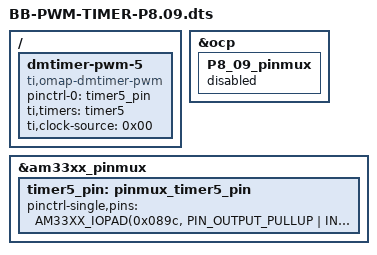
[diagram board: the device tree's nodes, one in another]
/*
 * Copyright (C) 2018 Robert Nelson <robertcnelson@gmail.com>
 *
 * This program is free software; you can redistribute it and/or modify
 * it under the terms of the GNU General Public License version 2 as
 * published by the Free Software Foundation.
 */

/dts-v1/;
/plugin/;

#include <dt-bindings/gpio/gpio.h>
#include <dt-bindings/pinctrl/am33xx.h>

/ {
	/*
	 * Free up the pins used by the cape from the pinmux helpers.
	 */
	fragment@0 {
		target = <&ocp>;
		__overlay__ {
			P8_09_pinmux { status = "disabled"; };	/* gpio2_5.timer5 */
		};
	};

	fragment@1 {
		target = <&am33xx_pinmux>;
		__overlay__ {
			timer5_pin: pinmux_timer5_pin {
				pinctrl-single,pins = <
					AM33XX_IOPAD(0x089c, PIN_OUTPUT_PULLUP | INPUT_EN | MUX_MODE2)	/* gpmc_be0n_cle.timer5 */
				>;
			};
		};
	};

	fragment@2 {
		target-path="/";
		__overlay__ {
			dmtimer-pwm-5 {
				pinctrl-names = "default";
				pinctrl-0 = <&timer5_pin>;

				compatible = "ti,omap-dmtimer-pwm";
				#pwm-cells = <3>;
				ti,timers = <&timer5>;
				//ti,prescaler = <0>;		/* 0 thru 7 */
				ti,clock-source = <0x00>;	/* timer_sys_ck */
				//ti,clock-source = <0x01>;	/* timer_32k_ck */
			};
		};
	};
};
